# EOS-S3 register map
File version: 0.1
CPU: CM4 r0p1, selectable endian, MPU, FPU, 3 interrupt priority bits
Registers are 32-bit, read-write, reset 0x0 unless marked. A register's access mark holds for its fields unless they carry their own. Offsets are from the block's base; [hi:lo] are bit positions; {n}, {i} and the like mark numbered series.

## ADC — Analog-to-Digital Converter
Base 0x40005A00
0x00 ADC_OUT ro — Last sampled value
  [11:0] OUT — Stored last sampled value
0x04 ADC_Status ro — Status
  [0] EOC — End of Conversion. Rises when data is valid
    0=non_valid (data in OUT field is not valid); 1=valid (data in OUT field is valid)
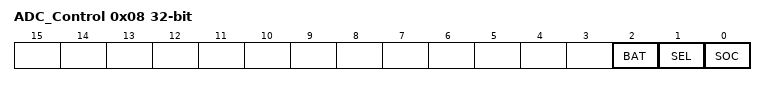
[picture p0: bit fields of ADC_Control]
0x08 ADC_Control — Control register
  [2] BAT — Battery measurement enable
    0=Disables battery measurement; 1=Enables battery measurement
  [1] SEL — Channel Selection. 0 = CH0, 1 = CH1
    0=select_ch0 (Select channel 0); 1=select_ch1 (Select channel 1)
  [0] SOC — Asynchronous start-of-conversion. Needs to rise and be held high for each conversion
    0=Stop conversion; 1=Start conversion. Needs to be held high until EOC is valid

## CFG_CTL — PIF Register (FPGA Programming interface)
Base 0x40014000
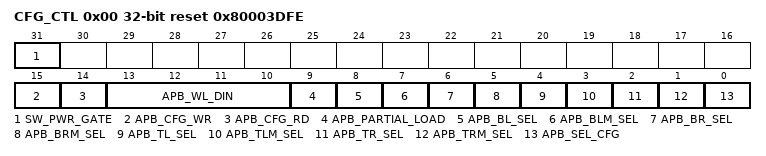
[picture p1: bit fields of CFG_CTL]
0x00 CFG_CTL reset 0x80003DFE — Fabric Configuration Control Register
  [31] SW_PWR_GATE — Shift Register Power Gate Status: 1 in configuration mode, 0 in normal mode
  [15] APB_CFG_WR — ARM firmware/software sets this register 1'b1 and APB_CFG_RD 1'b0 to perform Configuration Write
  [14] APB_CFG_RD — ARM firmware/software sets this register 1'b1 and APB_CFG_WR 1'b0 to perform Configuration Read
  [13:10] APB_WL_DIN — ARM firmware/software sets this register to set Word Line Data In
  [9] APB_PARTIAL_LOAD — ARM firmware/software sets this register 1'b1 to enable Partial Load
  [8] APB_BL_SEL — ARM firmware/software sets this register 1'b1 to Select BL Block
  [7] APB_BLM_SEL — ARM firmware/software sets this register 1'b1 to Select BLM Block
  [6] APB_BR_SEL — ARM firmware/software sets this register 1'b1 to Select BR Block
  [5] APB_BRM_SEL — ARM firmware/software sets this register 1'b1 to Select BRM Block
  [4] APB_TL_SEL — ARM firmware/software sets this register 1'b1 to Select TL Block
  [3] APB_TLM_SEL — ARM firmware/software sets this register 1'b1 to Select TLM Block
  [2] APB_TR_SEL — ARM firmware/software sets this register 1'b1 to Select TR Block
  [1] APB_TRM_SEL — ARM firmware/software sets this register 1'b1 to Select TRM Block
  [0] APB_SEL_CFG — ARM firmware/software sets this register 1'b1 to Get the Control Right of Cfg_Ctl
0x04 MAX_BL_CNT reset 0x2D — Maximum Bit Length Count: ARM firmware/software sets this register 1'b1 to set the Maximum Bit Line Count
0x08 MAX_WL_CNT reset 0x1A6 — Maximum Word Length Count: ARM firmware/software sets this register 1'b1 to set the Maximum Word Line Count
0xFFC CFG_DATA — Configuration Data: ARM firmware/software Access this register to Read/Write the configuration bit cells.
{0x4000+0x1000*i} RAMFIFO{i} (i=0..3) — RAMFIFO{i} Address: ARM firmware/software Access these registers to Read/Write the RAMFIFO{i}. From {0x8000+0x1000*i} to {0x8FFC+0x1000*i}.

## DMA — Direct Memory Access peripheral
Base 0x40007400
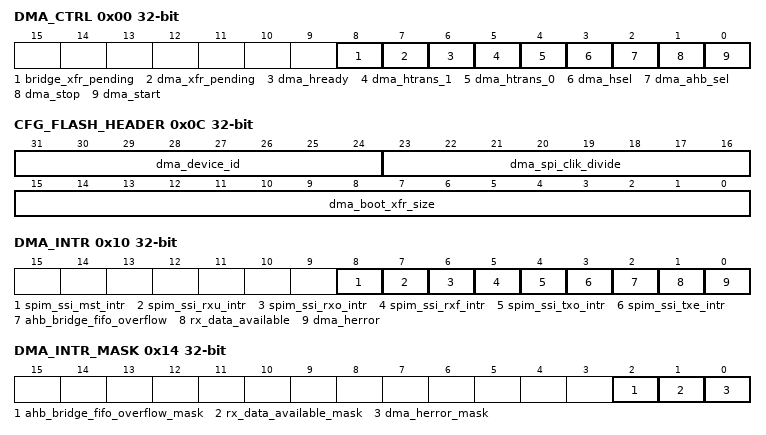
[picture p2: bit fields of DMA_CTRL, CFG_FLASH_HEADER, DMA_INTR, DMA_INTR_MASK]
0x00 DMA_CTRL (reset mask 0x7) — DMA Control : this register is only accessable when the dma or cfg_sm is not selecting the dmas_mux.
  [8] bridge_xfr_pending ro — 1: AHB bridge transfer is pending, 0: nothing pending
  [7] dma_xfr_pending ro — 1: DMA transfer is pending, 0: nothing pending
  [6] dma_hready ro — 1: AHB hready is asserted, 0: not asserted
  [5] dma_htrans_1 ro — 1: AHB htrans[1] is asserted, 0: not asserted
  [4] dma_htrans_0 ro — 1: AHB htrans[0] is asserted, 0: not asserted
  [3] dma_hsel ro — 1: AHB hsel is asserted, 0: not asserted
  [2] dma_ahb_sel — 0: DMA to AHB, 1: DMA to header register
  [1] dma_stop — write a 1: Stop DMA and disable, clears DMA_DONE, write a 0: no affect, reads dma_done
  [0] dma_start — write a 1: Enable, write a 0: no affect, reads dma_enb
0x00 CFG_MACHINE_ST_DELAY reset 0x1F4 (reset mask 0xFFF) — This is the delay value used in the config state machine. It is used for both deep sleep wakeup delay and between retries.
  [15:0] delay_reg — Delay value used in the config SM state machine. This is clocked at the APB pclk frequency. Default to decimal 500.
0x04 DMA_DEST_ADDR — DMA destination address : this register is only accessable when the dma or cfg_sm is not selecting the dmas_mux.
  [31:0] dma_dest_addr — DMA output data address : this register is only accessable when the dma or cfg_sm is not selecting the dmas_mux.
0x08 DMA_XFER_CNT — DMA transfer count in frames (8 bit) (minus 1) : this register is only accessable when the dma or cfg_sm is not selecting the dmas_mux.
  [25:0] dma_xfr_cnt — number of frames for DMA to transfer (minus 1). Max SPI transfer count is 2^16=64k frames
0x0C CFG_FLASH_HEADER — Header values read from EEPROM : this register is only accessable when the dma or cfg_sm is not selecting the dmas_mux.
  [31:24] dma_device_id ro — Device ID
  [23:16] dma_spi_clik_divide ro — SPI data clock out divides the ssi_clk (value in bytes*2)
  [15:0] dma_boot_xfr_size ro — number of double words (8 bytes) for the SPI to transfer (minus 1)
0x10 DMA_INTR (reset mask 0xFF) — DMA interrupts
  [8] spim_ssi_mst_intr ro — SPIM master interrupt
  [7] spim_ssi_rxu_intr ro — SPIM Receive FIFO underflow
  [6] spim_ssi_rxo_intr ro — SPIM Receive FIFO overflow
  [5] spim_ssi_rxf_intr ro — SPIM Receive FIFO threshold
  [4] spim_ssi_txo_intr ro — SPIM Transmit FIFO overflow
  [3] spim_ssi_txe_intr ro — SPIM Transmit FIFO empty
  [2] ahb_bridge_fifo_overflow ro — 1: A ahb FIFO bridge overflow occurred, 0: no overflow occurred
  [1] rx_data_available ro — 1: rx threshold was hit, 0:threshold was not hit. This is before external mask bit.
  [0] dma_herror ro — 1: hresp=1, 0: hresp didn't go to 1, write one to clr
0x14 DMA_INTR_MASK — DMA interrupt mask
  [all] fields
    0=Mask the interrupt; 1=Unmask the interrupt
  [2] ahb_bridge_fifo_overflow_mask — 1: Mask the ahb FIFO bridge overflow, 0: interrupts are enabled
  [1] rx_data_available_mask — 1: mask rx data available, 0:don't mask
  [0] dma_herror_mask — 1: disable interrupt, 0:enable interrupt
